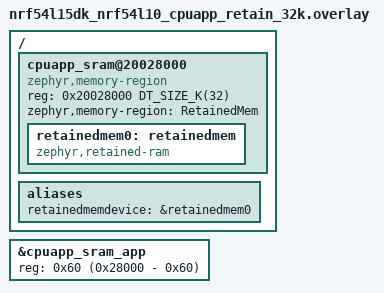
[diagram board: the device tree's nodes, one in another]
/ {
	cpuapp_sram@20028000 {
		compatible = "zephyr,memory-region", "mmio-sram";
		reg = <0x20028000 DT_SIZE_K(32)>;
		zephyr,memory-region = "RetainedMem";
		status = "okay";

		retainedmem0: retainedmem {
			compatible = "zephyr,retained-ram";
			status = "okay";
		};
	};

	aliases {
		retainedmemdevice = &retainedmem0;
	};
};

&cpuapp_sram_app {
	/* Shrink SRAM size to avoid overlap with retained memory region:
	 * 192 - 32 = 160KB = 0x28000
	 */
	reg = <0x60 (0x28000 - 0x60)>;
};
